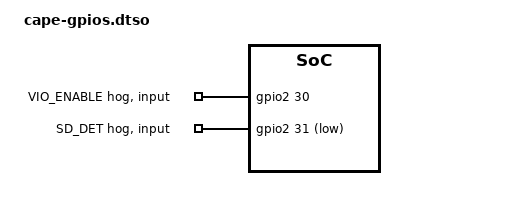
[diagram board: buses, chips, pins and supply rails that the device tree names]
// SPDX-License-Identifier: (GPL-2.0 OR MIT)
/* Copyright (c) 2020-2021 Microchip Technology Inc */

/dts-v1/;
/plugin/;

&{/} {
	fabric-bus@40000000 {
		cape_gpios_p8: gpio@41100000 {
			compatible = "microchip,core-gpio";
			reg = <0x0 0x41100000 0x0 0x1000>;
			clocks = <&fabric_clk3>;
			gpio-controller;
			#gpio-cells = <2>;
			ngpios=<16>;
			status = "okay";
			gpio-line-names = "P8_PIN31", "P8_PIN32", "P8_PIN33", "P8_PIN34",
			                  "P8_PIN35", "P8_PIN36", "P8_PIN37", "P8_PIN38",
			                  "P8_PIN39", "P8_PIN40", "P8_PIN41", "P8_PIN42",
							  "P8_PIN43", "P8_PIN44", "P8_PIN45", "P8_PIN46";
		};

		cape_gpios_p9: gpio@41200000 {
			compatible = "microchip,core-gpio";
			reg = <0x0 0x41200000 0x0 0x1000>;
			clocks = <&fabric_clk3>;
			gpio-controller;
			#gpio-cells = <2>;
			ngpios=<21>;
			status = "okay";
			gpio-line-names = "P9_PIN11", "P9_PIN12", "P9_PIN13", "P9_PIN14",
			                  "P9_PIN15", "P9_PIN16", "P9_PIN17", "P9_PIN18",
			                  "P9_PIN21", "P9_PIN22", "P9_PIN23", "P9_PIN24",
			                  "P9_PIN25", "P9_PIN26", "P9_PIN27", "P9_PIN28",
							  "P9_PIN29", "P9_PIN30", "P9_PIN31", "P9_PIN41", 
							  "P9_PIN42";
		};
	};
};

&gpio2 {
	interrupts = <53>, <53>, <53>, <53>,
		     <53>, <53>, <53>, <53>,
		     <53>, <53>, <53>, <53>,
		     <53>, <53>, <53>, <53>,
		     <53>, <53>, <53>, <53>,
		     <53>, <53>, <53>, <53>,
		     <53>, <53>, <53>, <53>,
		     <53>, <53>, <53>, <53>;
	gpio-line-names = "P8_PIN3_USER_LED_0", "P8_PIN4_USER_LED_1", "P8_PIN5_USER_LED_2",
					"P8_PIN6_USER_LED_3", "P8_PIN7_USER_LED_4", "P8_PIN8_USER_LED_5",
					"P8_PIN9_USER_LED_6", "P8_PIN10_USER_LED_7", "P8_PIN11_USER_LED_8",
					"P8_PIN12_USER_LED_9", "P8_PIN13_USER_LED_10", "P8_PIN14_USER_LED_11",
					"P8_PIN15", "P8_PIN16", "P8_PIN17", "P8_PIN18", "P8_PIN19",
					"P8_PIN20", "P8_PIN21", "P8_PIN22",	"P8_PIN23", "P8_PIN24",
					"P8_PIN25", "P8_PIN26", "P8_PIN27", "P8_PIN28", "P8_PIN29",
					"P8_PIN30",
					"M2_W_DISABLE1", "M2_W_DISABLE2",
					"VIO_ENABLE", "SD_DET";
	status = "okay";

	vio_enable {
		gpio-hog;
		gpios = <30 30>;
		output_high;
		line-name = "VIO_ENABLE";
	};

	sd_det {
		gpio-hog;
		gpios = <31 31>;
		input;
		line-name = "SD_DET";
	};
};
